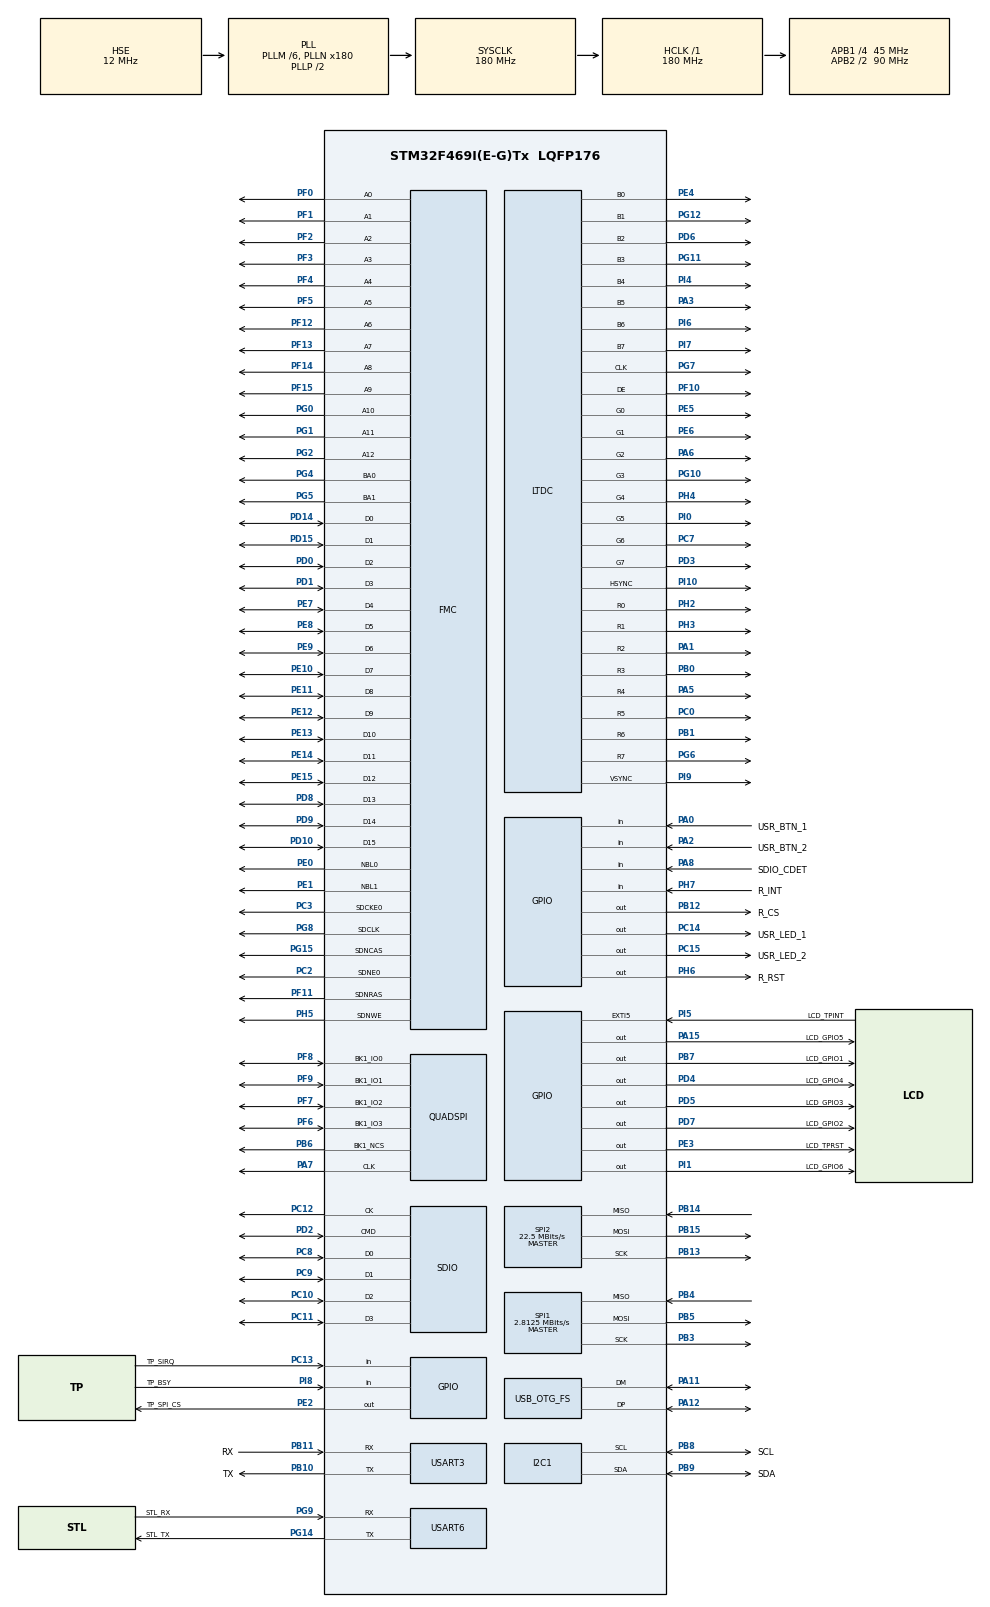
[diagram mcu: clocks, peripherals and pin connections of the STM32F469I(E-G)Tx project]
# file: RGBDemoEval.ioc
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FATFS.BSP.number=1
FATFS._USE_FIND=1
FATFS0.BSP.STBoard=false
FATFS0.BSP.api=Unknown
FATFS0.BSP.i2caddr=0
FATFS0.BSP.instance=PA8
FATFS0.BSP.ip=GPIO
FATFS0.BSP.mode=Input
FATFS0.BSP.name=Detect_SDIO
FATFS0.BSP.solution=PA8
FMC.CASLatency1=FMC_SDRAM_CAS_LATENCY_3
FMC.ExitSelfRefreshDelay1=7
FMC.LoadToActiveDelay1=2
FMC.RCDDelay1=2
FMC.RPDelay1=2
FMC.ReadPipeDelay1=FMC_SDRAM_RPIPE_DELAY_1
FMC.RowCycleDelay1=7
FMC.SDClockPeriod1=FMC_SDRAM_CLOCK_PERIOD_2
FMC.SelfRefreshTime1=4
FMC.WriteRecoveryTime1=3
I2C1.I2C_Mode=I2C_Fast
LTDC.ActiveH=240
LTDC.ActiveW=320
LTDC.Alpha0_L0=255
LTDC.Alpha0_L1=255
LTDC.Alpha_L0=255
LTDC.Alpha_L1=255
LTDC.Blue=0
LTDC.Blue_L0=0
LTDC.FBStartAdress_L0=0xc0000000
LTDC.FBStartAdress_L1=0xc0200000
LTDC.Green=0
LTDC.HBP=42
LTDC.HFP=7
LTDC.HSync=3
LTDC.ImageHeight_L0=600
LTDC.ImageHeight_L1=600
LTDC.ImageWidth_L0=1024
LTDC.Layers=0
LTDC.PCPolarity=LTDC_PCPOLARITY_IIPC
LTDC.PixelFormat_L0=LTDC_PIXEL_FORMAT_RGB565
LTDC.Red=0
LTDC.VBP=11
LTDC.VFP=7
LTDC.VSync=3
LTDC.WindowX1_L0=1024
LTDC.WindowX1_L1=1024
LTDC.WindowY1_L0=600
LTDC.WindowY1_L1=600
Mcu.Family=STM32F4
Mcu.Name=STM32F469I(E-G)Tx
Mcu.Package=LQFP176
NVIC.EXTI9_5_IRQn=true\:0\:0\:false\:false\:true\:true\:true
NVIC.PriorityGroup=NVIC_PRIORITYGROUP_4
PA0/WKUP.GPIO_Label=USR_BTN_1
PA0/WKUP.GPIO_PuPd=GPIO_PULLUP
PA0/WKUP.Signal=GPIO_Input
PA1.Mode=RGB888
PA1.Signal=LTDC_R2
PA11.Mode=Device_Only
PA11.Signal=USB_OTG_FS_DM
PA12.Mode=Device_Only
PA12.Signal=USB_OTG_FS_DP
PA13.Mode=Serial_Wire
PA13.Signal=SYS_JTMS-SWDIO
PA14.Mode=Serial_Wire
PA14.Signal=SYS_JTCK-SWCLK
PA15.GPIO_Label=LCD_GPIO5
PA15.Signal=GPIO_Output
PA2.GPIO_Label=USR_BTN_2
PA2.GPIO_PuPd=GPIO_PULLUP
PA2.Signal=GPIO_Input
PA3.Mode=RGB888
PA3.Signal=LTDC_B5
PA5.Mode=RGB888
PA5.Signal=LTDC_R4
PA6.Mode=RGB888
PA6.Signal=LTDC_G2
PA7.Mode=Single Bank 1
PA7.Signal=QUADSPI_CLK
PA8.GPIO_Label=SDIO_CDET
PA8.GPIO_PuPd=GPIO_PULLUP
PA8.Signal=GPIO_Input
PA9.Signal=USB_OTG_FS_VBUS
PB0.Mode=RGB888
PB0.Signal=LTDC_R3
PB1.Mode=RGB888
PB1.Signal=LTDC_R6
PB10.GPIO_Label=TX
PB10.Mode=Asynchronous
PB10.Signal=USART3_TX
PB11.GPIO_Label=RX
PB11.Mode=Asynchronous
PB11.Signal=USART3_RX
PB12.GPIO_Label=R_CS
PB12.Signal=GPIO_Output
PB13.Mode=Full_Duplex_Master
PB13.Signal=SPI2_SCK
PB14.Mode=Full_Duplex_Master
PB14.Signal=SPI2_MISO
PB15.Mode=Full_Duplex_Master
PB15.Signal=SPI2_MOSI
PB3.Mode=Full_Duplex_Master
PB3.Signal=SPI1_SCK
PB4.Mode=Full_Duplex_Master
PB4.Signal=SPI1_MISO
PB5.Mode=Full_Duplex_Master
PB5.Signal=SPI1_MOSI
PB6.Mode=Single Bank 1
PB6.Signal=QUADSPI_BK1_NCS
PB7.GPIO_Label=LCD_GPIO1
PB7.Signal=GPIO_Output
PB8.GPIO_Label=SCL
PB8.Mode=I2C
PB8.Signal=I2C1_SCL
PB9.GPIO_Label=SDA
PB9.Mode=I2C
PB9.Signal=I2C1_SDA
PC0.Mode=RGB888
PC0.Signal=LTDC_R5
PC10.Mode=SD_4_bits_Wide_bus
PC10.Signal=SDIO_D2
PC11.Mode=SD_4_bits_Wide_bus
PC11.Signal=SDIO_D3
PC12.Mode=SD_4_bits_Wide_bus
PC12.Signal=SDIO_CK
PC13.GPIO_Label=TP_SIRQ
PC13.GPIO_PuPd=GPIO_NOPULL
PC13.Signal=GPIO_Input
PC14/OSC32_IN.GPIO_Label=USR_LED_1
PC14/OSC32_IN.Signal=GPIO_Output
PC15/OSC32_OUT.GPIO_Label=USR_LED_2
PC15/OSC32_OUT.Signal=GPIO_Output
PC2.Mode=SdramChipSelect1_1
PC2.Signal=FMC_SDNE0
PC3.Mode=SdramChipSelect1_1
PC3.Signal=FMC_SDCKE0
PC7.Mode=RGB888
PC7.Signal=LTDC_G6
PC8.Mode=SD_4_bits_Wide_bus
PC8.Signal=SDIO_D0
PC9.Mode=SD_4_bits_Wide_bus
PC9.Signal=SDIO_D1
PD0.Signal=FMC_D2_DA2
PD1.Signal=FMC_D3_DA3
PD10.Signal=FMC_D15_DA15
PD14.Signal=FMC_D0_DA0
PD15.Signal=FMC_D1_DA1
PD2.Mode=SD_4_bits_Wide_bus
PD2.Signal=SDIO_CMD
PD3.Mode=RGB888
PD3.Signal=LTDC_G7
PD4.GPIO_Label=LCD_GPIO4
PD4.Signal=GPIO_Output
PD5.GPIO_Label=LCD_GPIO3
PD5.Signal=GPIO_Output
PD6.Mode=RGB888
PD6.Signal=LTDC_B2
PD7.GPIO_Label=LCD_GPIO2
PD7.Signal=GPIO_Output
PD8.Signal=FMC_D13_DA13
PD9.Signal=FMC_D14_DA14
PE0.Signal=FMC_NBL0
PE1.Signal=FMC_NBL1
PE10.Signal=FMC_D7_DA7
PE11.Signal=FMC_D8_DA8
PE12.Signal=FMC_D9_DA9
PE13.Signal=FMC_D10_DA10
PE14.Signal=FMC_D11_DA11
PE15.Signal=FMC_D12_DA12
PE2.GPIO_Label=TP_SPI_CS
PE2.Signal=GPIO_Output
PE3.GPIO_Label=LCD_TPRST
PE3.Signal=GPIO_Output
PE4.Mode=RGB888
PE4.Signal=LTDC_B0
PE5.Mode=RGB888
PE5.Signal=LTDC_G0
PE6.Mode=RGB888
PE6.Signal=LTDC_G1
PE7.Signal=FMC_D4_DA4
PE8.Signal=FMC_D5_DA5
PE9.Signal=FMC_D6_DA6
PF0.Signal=FMC_A0
PF1.Signal=FMC_A1
PF10.Mode=RGB888
PF10.Signal=LTDC_DE
PF11.Signal=FMC_SDNRAS
PF12.Signal=FMC_A6
PF13.Signal=FMC_A7
PF14.Signal=FMC_A8
PF15.Signal=FMC_A9
PF2.Signal=FMC_A2
PF3.Signal=FMC_A3
PF4.Signal=FMC_A4
PF5.Signal=FMC_A5
PF6.Mode=Single Bank 1
PF6.Signal=QUADSPI_BK1_IO3
PF7.Mode=Single Bank 1
PF7.Signal=QUADSPI_BK1_IO2
PF8.Mode=Single Bank 1
PF8.Signal=QUADSPI_BK1_IO0
PF9.Mode=Single Bank 1
PF9.Signal=QUADSPI_BK1_IO1
PG0.Signal=FMC_A10
PG1.Signal=FMC_A11
PG10.Mode=RGB888
PG10.Signal=LTDC_G3
PG11.Mode=RGB888
PG11.Signal=LTDC_B3
PG12.Mode=RGB888
PG12.Signal=LTDC_B1
PG14.GPIO_Label=STL_TX
PG14.Mode=Asynchronous
PG14.Signal=USART6_TX
PG15.Signal=FMC_SDNCAS
PG2.Signal=FMC_A12
PG4.Signal=FMC_A14_BA0
PG5.Signal=FMC_A15_BA1
PG6.Mode=RGB888
PG6.Signal=LTDC_R7
PG7.Mode=RGB888
PG7.Signal=LTDC_CLK
PG8.Signal=FMC_SDCLK
PG9.GPIO_Label=STL_RX
PG9.Mode=Asynchronous
PG9.Signal=USART6_RX
PH0/OSC_IN.Mode=HSE-External-Oscillator
PH0/OSC_IN.Signal=RCC_OSC_IN
PH1/OSC_OUT.Mode=HSE-External-Oscillator
PH1/OSC_OUT.Signal=RCC_OSC_OUT
PH2.Mode=RGB888
PH2.Signal=LTDC_R0
PH3.Mode=RGB888
PH3.Signal=LTDC_R1
PH4.Mode=RGB888
PH4.Signal=LTDC_G4
PH5.Signal=FMC_SDNWE
PH6.GPIO_Label=R_RST
PH6.Signal=GPIO_Output
PH7.GPIO_Label=R_INT
PH7.Signal=GPIO_Input
PI0.Mode=RGB888
PI0.Signal=LTDC_G5
PI1.GPIO_Label=LCD_GPIO6
PI1.Signal=GPIO_Output
PI10.Mode=RGB888
PI10.Signal=LTDC_HSYNC
PI4.Mode=RGB888
PI4.Signal=LTDC_B4
PI5.GPIO_Label=LCD_TPINT
PI5.Signal=GPXTI5
PI6.Mode=RGB888
PI6.Signal=LTDC_B6
PI7.Mode=RGB888
PI7.Signal=LTDC_B7
PI8.GPIO_Label=TP_BSY
PI8.Signal=GPIO_Input
PI9.Mode=RGB888
PI9.Signal=LTDC_VSYNC
ProjectManager.HeapSize=0x200
ProjectManager.StackSize=0x400
ProjectManager.TargetToolchain=STM32CubeIDE
QUADSPI.ChipSelectHighTime=QSPI_CS_HIGH_TIME_8_CYCLE
QUADSPI.ClockPrescaler=4
QUADSPI.FlashSize=23
RCC.AHBFreq_Value=180000000
RCC.APB1CLKDivider=RCC_HCLK_DIV4
RCC.APB1Freq_Value=45000000
RCC.APB1TimFreq_Value=90000000
RCC.APB2CLKDivider=RCC_HCLK_DIV2
RCC.APB2Freq_Value=90000000
RCC.APB2TimFreq_Value=180000000
RCC.CortexFreq_Value=180000000
RCC.HCLKFreq_Value=180000000
RCC.HSE_VALUE=12000000
RCC.HSI_VALUE=16000000
RCC.LSE_VALUE=32768
RCC.PLLM=6
RCC.PLLN=180
RCC.PLLQ=7
RCC.PLLSAIP=RCC_PLLSAIP_DIV8
RCC.PLLSAIR=4
RCC.PLLSAIRDiv=RCC_PLLSAIDIVR_16
RCC.PLLSourceVirtual=RCC_PLLSOURCE_HSE
RCC.SYSCLKFreq_VALUE=180000000
RCC.SYSCLKSource=RCC_SYSCLKSOURCE_PLLCLK
RCC.USBCLockSelection=RCC_CLK48CLKSOURCE_PLLSAIP
RCC.USBFreq_Value=48000000
RCC.VCOOutputFreq_Value=360000000
SDIO.ClockDiv=16
SDIO.ClockEdge=SDIO_CLOCK_EDGE_RISING
SDIO.HardwareFlowControl=SDIO_HARDWARE_FLOW_CONTROL_ENABLE
SH.FMC_A0.0=FMC_A0,13b-sda1
SH.FMC_A1.0=FMC_A1,13b-sda1
SH.FMC_A10.0=FMC_A10,13b-sda1
SH.FMC_A11.0=FMC_A11,13b-sda1
SH.FMC_A12.0=FMC_A12,13b-sda1
SH.FMC_A14_BA0.0=FMC_BA0,FourSdramBanks1
SH.FMC_A15_BA1.0=FMC_BA1,FourSdramBanks1
SH.FMC_A2.0=FMC_A2,13b-sda1
SH.FMC_A3.0=FMC_A3,13b-sda1
SH.FMC_A4.0=FMC_A4,13b-sda1
SH.FMC_A5.0=FMC_A5,13b-sda1
SH.FMC_A6.0=FMC_A6,13b-sda1
SH.FMC_A7.0=FMC_A7,13b-sda1
SH.FMC_A8.0=FMC_A8,13b-sda1
SH.FMC_A9.0=FMC_A9,13b-sda1
SH.FMC_D0_DA0.0=FMC_D0,sd-16b-d1
SH.FMC_D10_DA10.0=FMC_D10,sd-16b-d1
SH.FMC_D11_DA11.0=FMC_D11,sd-16b-d1
SH.FMC_D12_DA12.0=FMC_D12,sd-16b-d1
SH.FMC_D13_DA13.0=FMC_D13,sd-16b-d1
SH.FMC_D14_DA14.0=FMC_D14,sd-16b-d1
SH.FMC_D15_DA15.0=FMC_D15,sd-16b-d1
SH.FMC_D1_DA1.0=FMC_D1,sd-16b-d1
SH.FMC_D2_DA2.0=FMC_D2,sd-16b-d1
SH.FMC_D3_DA3.0=FMC_D3,sd-16b-d1
SH.FMC_D4_DA4.0=FMC_D4,sd-16b-d1
SH.FMC_D5_DA5.0=FMC_D5,sd-16b-d1
SH.FMC_D6_DA6.0=FMC_D6,sd-16b-d1
SH.FMC_D7_DA7.0=FMC_D7,sd-16b-d1
SH.FMC_D8_DA8.0=FMC_D8,sd-16b-d1
SH.FMC_D9_DA9.0=FMC_D9,sd-16b-d1
SH.FMC_NBL0.0=FMC_NBL0,Sd2ByteEnable1
SH.FMC_NBL1.0=FMC_NBL1,Sd2ByteEnable1
SH.FMC_SDCLK.0=FMC_SDCLK,13b-sda1
SH.FMC_SDNCAS.0=FMC_SDNCAS,13b-sda1
SH.FMC_SDNRAS.0=FMC_SDNRAS,13b-sda1
SH.FMC_SDNWE.0=FMC_SDNWE,13b-sda1
SPI1.BaudRatePrescaler=SPI_BAUDRATEPRESCALER_32
SPI1.CalculateBaudRate=2.8125 MBits/s
SPI1.Direction=SPI_DIRECTION_2LINES
SPI1.Mode=SPI_MODE_MASTER
SPI1.VirtualType=VM_MASTER
SPI2.BaudRatePrescaler=SPI_BAUDRATEPRESCALER_2
SPI2.CalculateBaudRate=22.5 MBits/s
SPI2.Direction=SPI_DIRECTION_2LINES
SPI2.Mode=SPI_MODE_MASTER
SPI2.VirtualType=VM_MASTER
USART3.VirtualMode=VM_ASYNC
USART6.VirtualMode=VM_ASYNC
USB_OTG_FS.Sof_enable=DISABLE
USB_OTG_FS.VirtualMode=Device_Only
USB_OTG_FS.low_power_enable=DISABLE
VP_FATFS_VS_SDIO.Mode=SDIO
board=custom

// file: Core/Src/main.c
/* USER CODE BEGIN Header */
/**
  ******************************************************************************
  * @file           : main.c
  * @brief          : Main program body
  ******************************************************************************
  * @attention
  *
  * <h2><center>&copy; Copyright (c) 2020 STMicroelectronics.
  * All rights reserved.</center></h2>
  *
  * This software component is licensed by ST under Ultimate Liberty license
  * SLA0044, the "License"; You may not use this file except in compliance with
  * the License. You may obtain a copy of the License at:
  *                             www.st.com/SLA0044
  *
  ******************************************************************************
  */
/* USER CODE END Header */
#include "main.h"
#include "fatfs.h"
#include "i2c.h"
#include "ltdc.h"
#include "quadspi.h"
#include "sdio.h"
#include "spi.h"
#include "usart.h"
#include "usb_otg.h"
#include "gpio.h"
#include "fmc.h"

/* USER CODE BEGIN Includes */

#include "bsp_adc_touch.h"
#include "bsp_button.h"
#include "bsp_display.h"
#include "bsp_flash.h"
#include "bsp_led.h"
#include "bsp_print.h"
#include "bsp_ribus.h"
#include "bsp_sdcard.h"
#include "bsp_sdram.h"
#include "bsp_touch.h"
#include "bsp_sdcard.h"
#include "demo.h"
#include <string.h>
/* USER CODE END Includes */

void SystemClock_Config(void);

int main(void)
{

  /* MCU Configuration--------------------------------------------------------*/

  /* Reset of all peripherals, Initializes the Flash interface and the Systick. */
  HAL_Init();

  /* USER CODE BEGIN Init */
//  SCB->VTOR = 0x10000;
//  __enable_irq();
  /* USER CODE END Init */

  /* Configure the system clock */
  SystemClock_Config();

  /* Initialize all configured peripherals */
  MX_GPIO_Init();
  MX_FMC_Init();
  MX_I2C1_Init();
  MX_LTDC_Init();
  MX_QUADSPI_Init();
  MX_SDIO_SD_Init();
  MX_SPI1_Init();
  MX_SPI2_Init();
  MX_USART3_UART_Init();
  MX_USART6_UART_Init();
  MX_FATFS_Init();
  MX_USB_OTG_FS_PCD_Init();
  /* USER CODE BEGIN 2 */

  // -------------------------------------- Initialization

  BSP_SDRAM_Initliazation( );
  BSP_Print( "\r\n\r\n------------------" );
  BSP_Print( "\r\nGetting display and TP info\r\n" );

  memset(0xc0000000, 0xFF, 1024*600*2 );

//  if ( DEMO_DisplaySizeSelection( ) )
//  {
//    BSP_Print( "\r\n\tLoad configuration from flash" );
//    //DEMO_RestoreConfiguratiion( );
//  }
//  else
//  {
//	DEMO_DisplayTypeSelection( );
//
//    if ( DEMO_RibusDisplayQuery( ) )
//	{
//	  BSP_Print( "\r\n\tRiBUS Display found" );
//	}
//
//    DEMO_StoreConfiguratiion( );
//  }

  BSP_Print( "\r\n\r\n------------------" );
  BSP_Print( "\r\nInitlization display and TP\r\n" );

  DEMO_Initialize( );

   HAL_Delay( 20 );

  /* USER CODE END 2 */

  /* Infinite loop */
  while (1)
  {

    /* USER CODE BEGIN 3 */

	DEMO_Run( );
  }
  /* USER CODE END 3 */
}

void SystemClock_Config(void)
{
  RCC_OscInitTypeDef RCC_OscInitStruct = {0};
  RCC_ClkInitTypeDef RCC_ClkInitStruct = {0};
  RCC_PeriphCLKInitTypeDef PeriphClkInitStruct = {0};

  /** Configure the main internal regulator output voltage
  */
  __HAL_RCC_PWR_CLK_ENABLE();
  __HAL_PWR_VOLTAGESCALING_CONFIG(PWR_REGULATOR_VOLTAGE_SCALE1);
  /** Initializes the RCC Oscillators according to the specified parameters
  * in the RCC_OscInitTypeDef structure.
  */
  RCC_OscInitStruct.OscillatorType = RCC_OSCILLATORTYPE_HSE;
  RCC_OscInitStruct.HSEState = RCC_HSE_ON;
  RCC_OscInitStruct.PLL.PLLState = RCC_PLL_ON;
  RCC_OscInitStruct.PLL.PLLSource = RCC_PLLSOURCE_HSE;
  RCC_OscInitStruct.PLL.PLLM = 6;
  RCC_OscInitStruct.PLL.PLLN = 180;
  RCC_OscInitStruct.PLL.PLLP = RCC_PLLP_DIV2;
  RCC_OscInitStruct.PLL.PLLQ = 7;
  RCC_OscInitStruct.PLL.PLLR = 2;
  if (HAL_RCC_OscConfig(&RCC_OscInitStruct) != HAL_OK)
  {
    Error_Handler();
  }
  /** Activate the Over-Drive mode
  */
  if (HAL_PWREx_EnableOverDrive() != HAL_OK)
  {
    Error_Handler();
  }
  /** Initializes the CPU, AHB and APB buses clocks
  */
  RCC_ClkInitStruct.ClockType = RCC_CLOCKTYPE_HCLK|RCC_CLOCKTYPE_SYSCLK
                              |RCC_CLOCKTYPE_PCLK1|RCC_CLOCKTYPE_PCLK2;
  RCC_ClkInitStruct.SYSCLKSource = RCC_SYSCLKSOURCE_PLLCLK;
  RCC_ClkInitStruct.AHBCLKDivider = RCC_SYSCLK_DIV1;
  RCC_ClkInitStruct.APB1CLKDivider = RCC_HCLK_DIV4;
  RCC_ClkInitStruct.APB2CLKDivider = RCC_HCLK_DIV2;

  if (HAL_RCC_ClockConfig(&RCC_ClkInitStruct, FLASH_LATENCY_5) != HAL_OK)
  {
    Error_Handler();
  }
  PeriphClkInitStruct.PeriphClockSelection = RCC_PERIPHCLK_SDIO|RCC_PERIPHCLK_CLK48
                              |RCC_PERIPHCLK_LTDC;
  PeriphClkInitStruct.PLLSAI.PLLSAIN = 192;
  PeriphClkInitStruct.PLLSAI.PLLSAIR = 4;
  PeriphClkInitStruct.PLLSAI.PLLSAIP = RCC_PLLSAIP_DIV8;
  PeriphClkInitStruct.PLLSAIDivR = RCC_PLLSAIDIVR_16;
  PeriphClkInitStruct.Clk48ClockSelection = RCC_CLK48CLKSOURCE_PLLSAIP;
  PeriphClkInitStruct.SdioClockSelection = RCC_SDIOCLKSOURCE_CLK48;
  if (HAL_RCCEx_PeriphCLKConfig(&PeriphClkInitStruct) != HAL_OK)
  {
    Error_Handler();
  }
}

void Error_Handler(void)
{
}

/************************ (C) COPYRIGHT STMicroelectronics *****END OF FILE****/
